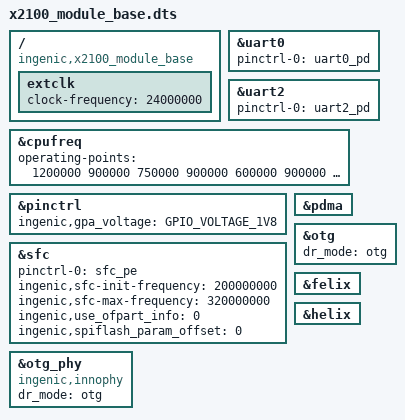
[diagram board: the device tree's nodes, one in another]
/dts-v1/;

#include <dt-bindings/input/input.h>
#include "x2100.dtsi"
#include <dt-bindings/interrupt-controller/irq.h>
#include <generated/autoconf.h>

/ {
	compatible = "ingenic,x2100_module_base", "ingenic,x2100";
};

&uart0 {
	status = "okay";
	pinctrl-names = "default";
	pinctrl-0 = <&uart0_pd>;
};

&uart2 {
	status = "okay";
	pinctrl-names = "default";
	pinctrl-0 = <&uart2_pd>;
};

&cpufreq {
	status = "okay";
	operating-points = <
		/*KHZ uV */
		1200000	900000
		750000	900000
		600000	900000
		500000	900000
		400000	900000
		375000	900000
		300000	900000
		200000	900000
			>;

};

&pinctrl {
	ingenic,gpa_voltage = <GPIO_VOLTAGE_1V8>;
};

&pdma {
	status = "okay";
};

&sfc {
	status = "okay";
	pinctrl-names = "default";
	pinctrl-0 = <&sfc_pe>;
	ingenic,sfc-init-frequency = <200000000>;
	ingenic,sfc-max-frequency = <320000000>;
	ingenic,use_ofpart_info  = /bits/ 8 <0>;
	ingenic,spiflash_param_offset = <0>;


};

&otg {
	// g-use-dma;
	dr_mode = "otg";
	status = "okay";
};

&otg_phy {
	dr_mode = "otg";
	compatible = "ingenic,innophy", "syscon";
	status = "okay";
};

&felix {
	status = "okay";
};

&helix {
	status = "okay";
};

/ {

	extclk: extclk {
		clock-frequency = <24000000>;
	};

	};
